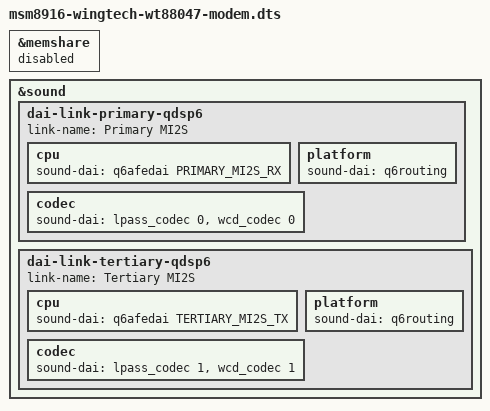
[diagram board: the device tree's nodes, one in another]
// SPDX-License-Identifier: GPL-2.0-only
#include "msm8916-wingtech-wt88047.dts"
#include "msm8916-modem.dtsi"

/*
 * The modem firmware sends a "query_size" memshare request for client ID 1,
 * but basically does not do anything with it. GPS works only if:
 *   - Memshare is not present or
 *   - Memshare replies to the request with an error
 * Overall it seems pointless to enable memshare for this device.
 */
&memshare {
	status = "disabled";
};

&sound {
	/delete-node/ dai-link-primary;
	/delete-node/ dai-link-tertiary;

	dai-link-primary-qdsp6 {
		link-name = "Primary MI2S";
		cpu {
			sound-dai = <&q6afedai PRIMARY_MI2S_RX>;
		};
		platform {
			sound-dai = <&q6routing>;
		};
		codec {
			sound-dai = <&lpass_codec 0>, <&wcd_codec 0>;
		};
	};

	dai-link-tertiary-qdsp6 {
		link-name = "Tertiary MI2S";
		cpu {
			sound-dai = <&q6afedai TERTIARY_MI2S_TX>;
		};
		platform {
			sound-dai = <&q6routing>;
		};
		codec {
			sound-dai = <&lpass_codec 1>, <&wcd_codec 1>;
		};
	};
};
